# MIMXRT685S_cm33 register map
Vendor: nxp.com; File version: 1.0
CPU: CM33 r2p0, little endian, MPU, FPU, VTOR, 3 interrupt priority bits
Registers are 32-bit, read-write, reset 0x0 unless marked. A register's access mark holds for its fields unless they carry their own. Offsets are from the block's base; [hi:lo] are bit positions; {n}, {i} and the like mark numbered series; 'fields as' and 'values as' point back to an identical list.

## CLKCTL0 — clock ccontroller 0
Base 0x40001000
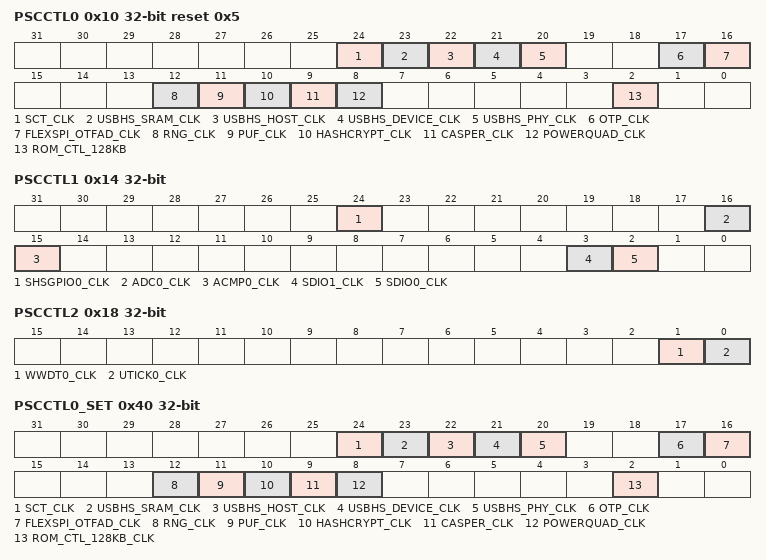
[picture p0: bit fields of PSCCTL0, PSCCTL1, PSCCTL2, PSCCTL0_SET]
0x10 PSCCTL0 reset 0x5 — clock control register 0
  [all] fields
    0=DISABLE_CLOCK; 1=ENABLE_CLOCK
  [24] SCT_CLK — SCT clock control
  [23] USBHS_SRAM_CLK — USBHS RAM clock control
  [22] USBHS_HOST_CLK — USB HOST clock control
  [21] USBHS_DEVICE_CLK — USB DEVICE clock control
  [20] USBHS_PHY_CLK — USB PHY clock control
  [17] OTP_CLK — OTP clock control
  [16] FLEXSPI_OTFAD_CLK — FLEXSPI clock control
  [12] RNG_CLK — RNG clock control
  [11] PUF_CLK — PUF clock control
  [10] HASHCRYPT_CLK — HASHCRYPT clock control
  [9] CASPER_CLK — CAPSER clock control
  [8] POWERQUAD_CLK — powerquad clock control
  [2] ROM_CTL_128KB — 128KB ROM control
0x14 PSCCTL1 — clock control register 1
  [all] fields
    0=DISABLE_CLOCK; 1=ENABLE_CLOCK
  [24] SHSGPIO0_CLK — SHSGPIO0 clock control
  [16] ADC0_CLK — ADC clock control
  [15] ACMP0_CLK — Analog comparator clock control
  [3] SDIO1_CLK — SDIO1 clock control
  [2] SDIO0_CLK — SDIO0 clock control
0x18 PSCCTL2 — clock control register 2
  [1] WWDT0_CLK — wdt clock control
    0=DISABLE_CLOCK; 1=ENABLE_CLOCK
  [0] UTICK0_CLK — utick clock control
    0=DISABLE_CLOCK; 1=ENABLE_CLOCK
0x40 PSCCTL0_SET reset not defined — clock set register 0
  [all] fields
    0=NO_EFFECT; 1=SET_CLOCK (Sets the PSCCTL0 Bit)
  [24] SCT_CLK wo — SCT clock set
  [23] USBHS_SRAM_CLK wo — USBHS RAM clock set
  [22] USBHS_HOST_CLK wo — USB HOST clock set
  [21] USBHS_DEVICE_CLK wo — USB DEVICE clock set
  [20] USBHS_PHY_CLK wo — USB PHY clock set
  [17] OTP_CLK wo — OTP clock set
  [16] FLEXSPI_OTFAD_CLK wo — FLEXSPI clock set
  [12] RNG_CLK wo — RNG clock set
  [11] PUF_CLK wo — PUF clock set
  [10] HASHCRYPT_CLK wo — HASHCRYPT clock set
  [9] CASPER_CLK wo — CAPSER clock set
  [8] POWERQUAD_CLK wo — powerquad clock set
  [2] ROM_CTL_128KB_CLK wo — 128KB ROM controller clock set
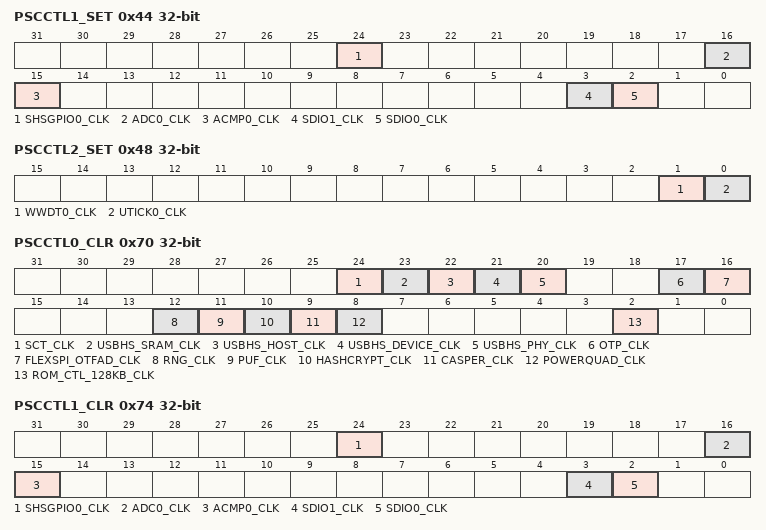
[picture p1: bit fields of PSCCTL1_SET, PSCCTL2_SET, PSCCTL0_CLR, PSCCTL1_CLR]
0x44 PSCCTL1_SET wo reset not defined — clock set register 1
  [all] fields
    0=NO_EFFECT; 1=SET_CLOCK (Sets the PSCCTL1 Bit)
  [24] SHSGPIO0_CLK — SHSGPIO0 clock set
  [16] ADC0_CLK — ADC clock set
  [15] ACMP0_CLK — Analog comparator clock set
  [3] SDIO1_CLK — SDIO1 clock set
  [2] SDIO0_CLK — SDIO0 clock set
0x48 PSCCTL2_SET wo reset not defined — clock set register 2
  [1] WWDT0_CLK — wdt clock set
    0=NO_EFFECT; 1=SET_CLOCK (Sets the PSCCTL2 Bit)
  [0] UTICK0_CLK — utick clock set
    0=NO_EFFECT; 1=SET_CLOCK (Sets the PSCCTL2 Bit)
0x70 PSCCTL0_CLR reset not defined — clock clear register 0
  [all] fields
    0=NO_EFFECT; 1=CLR_CLOCK (Clears the PSCCTL0 Bit)
  [24] SCT_CLK wo — SCT clock clear
  [23] USBHS_SRAM_CLK wo — USBHS RAM clock clear
  [22] USBHS_HOST_CLK wo — USB HOST clock clear
  [21] USBHS_DEVICE_CLK wo — USB DEVICE clock clear
  [20] USBHS_PHY_CLK wo — USB PHY clock clear
  [17] OTP_CLK wo — OTP clock clear
  [16] FLEXSPI_OTFAD_CLK wo — FLEXSPI clock clear
  [12] RNG_CLK wo — RNG clock clear
  [11] PUF_CLK wo — PUF clock clear
  [10] HASHCRYPT_CLK wo — HASHCRYPT clock clear
  [9] CASPER_CLK wo — CAPSER clock clear
  [8] POWERQUAD_CLK wo — powerquad clock clear
  [2] ROM_CTL_128KB_CLK wo — ROM controller clock clear
0x74 PSCCTL1_CLR wo reset not defined — clock clear register 1
  [all] fields
    0=NO_EFFECT; 1=CLR_CLOCK (Clears the PSCCTL1 Bit)
  [24] SHSGPIO0_CLK — SHSGPIO0 clock clear
  [16] ADC0_CLK — ADC clock clear
  [15] ACMP0_CLK — Analog comparator clock clear
  [3] SDIO1_CLK — SDIO1 clock clear
  [2] SDIO0_CLK — SDIO0 clock clear
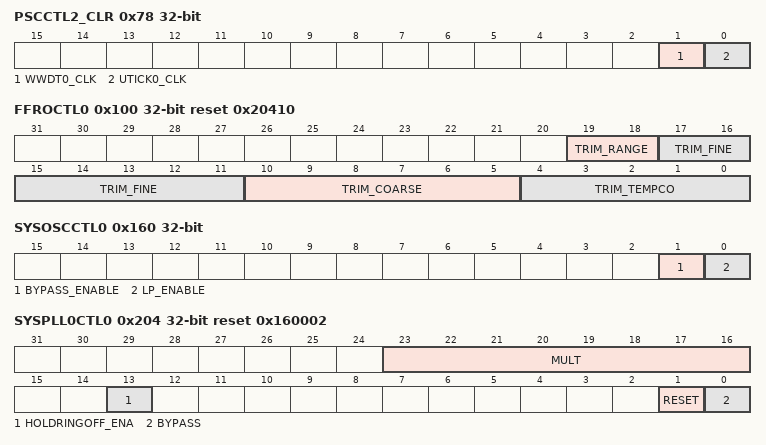
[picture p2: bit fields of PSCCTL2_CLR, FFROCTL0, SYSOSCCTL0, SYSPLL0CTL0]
0x78 PSCCTL2_CLR wo reset not defined — clock clear register 2
  [1] WWDT0_CLK — wdt clock clear
    0=NO_EFFECT; 1=CLR_CLOCK (Clears the PSCCTL2 Bit)
  [0] UTICK0_CLK — utick clock clear
    0=NO_EFFECT; 1=CLR_CLOCK (Clears the PSCCTL2 Bit)
0x100 FFROCTL0 reset 0x20410 — FFRO control 0
  [19:18] TRIM_RANGE — Trims frequency range of FFRO.
    0=FFRO_48MHz (48MHz.); 3=FFRO_60MHz (60MHz.)
  [17:11] TRIM_FINE — Trims fine frequency of FFRO.
  [10:5] TRIM_COARSE — Trims coarse frequency of FFRO.
  [4:0] TRIM_TEMPCO — Trims temperature compensation of FFRO.
0x104 FFROCTL1 — FFRO control 1
  [0] UPDATE — Update Safe Mode Control. In order to change any of the TRIM values, the user first needs to set the update safe mode bit, then proceed to change the respective TRIM values needed, followed by clearing the update safe mode bit.
    0=NORMAL_MODE; 1=UPDATE_SAFE_MODE
0x160 SYSOSCCTL0 — system oscillator control 0
  [1] BYPASS_ENABLE — Enable signal for external bypass clock. . .
    0=NORMAL_MODE; 1=BYPASS_MODE
  [0] LP_ENABLE — Enable signal for low power mode. . .
    0=HP (High Gain Mode(HP).); 1=LP (Low Power mode (LP).)
0x168 SYSOSCBYPASS — system oscillator bypass
  [2:0] SEL — Extenal Clock Source Selection.
    0=EXT_XTAL_CLK (External XTAL Clock.); 1=CLOCK_IN_CLK (Clock IN Clock.); 7=NONE (NONE.this may be selected in order to reduce power when no output is needed.)
0x190 LPOSCCTL0 reset 0x807BC4D4 — low power oscillator control 0
  [31] CLKRDY — Clock ready flag status. LPOSC clock ready takes 64uS.
0x1C0 OSC32KHZCTL0 — 32k oscillator control0
  [0] ENA32KHZ — 32KHz Enable.
    0=DISABLED; 1=ENABLED
0x200 SYSPLL0CLKSEL reset 0x7 — system pll0 clock selection
  [2:0] SEL — System PLL Clock Source Selection. . .
    0=SFRO_CLK (SFRO Clock.); 1=SYSXTAL_CLK (SYSXTALIN Clock.); 2=FFRO_DIV_2 (FFRO Clock Divided by 2.); 7=NONE (None, this may be selected in order to reduce power when no output is needed.)
0x204 SYSPLL0CTL0 reset 0x160002 — system pll0 control0
  [23:16] MULT — Multiplication Factor for FSYSPLL0_OUTPUT:
    16=DIV_16; 17=DIV_17; 20=DIV_20; 22=DIV_22; 27=DIV_27; 33=DIV_33
  [13] HOLDRINGOFF_ENA — Hold Ring Off Control: This bit is used to avoid multi wave within the VCO.
    0=DSIABLE (disbale); 1=ENABLE
  [1] RESET — SYSPLL0 Reset:
    0=NORMAL (SYSPLL0 reset is removed.); 1=FORCED_INTO_RESET (SYSPLL0 is placed into reset.)
  [0] BYPASS — SYSPLL0 BYPASS Mode
    0=PROGRAMMED_CLK (PFD output is PFD programmed clock.); 1=BYPASS (PFD output is PLL Input clock. (Bypass))
0x20C SYSPLL0LOCKTIMEDIV2 reset 0xCAFE — system pll0 lock time
  [15:0] LOCKTIMEDIV2 — SYSPLL0 Lock Time Divide by 2: Programmed lock time is in uS (micro-seconds) and is programmed as half the actual lock time value.
0x210 SYSPLL0NUM reset 0x4DD2F15 — system pll0 number
  [29:0] NUM — This field contains the numerator of the SYSPLL0 fractional loop divider.
0x214 SYSPLL0DENOM reset 0x1FFFFFDB — system pll0 denom
  [29:0] DENOM — This field contains the denominator of the SYSPLL0 fractional loop divider.
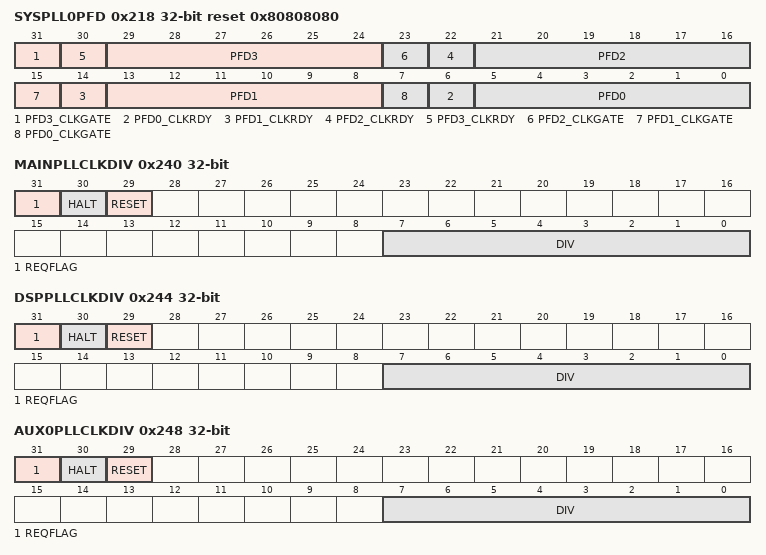
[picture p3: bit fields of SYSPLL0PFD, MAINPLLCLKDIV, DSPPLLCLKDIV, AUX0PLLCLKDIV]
0x218 SYSPLL0PFD reset 0x80808080
  [31] PFD3_CLKGATE — PFD3 Clock Gate: 0: PFD3 clock is not gated. 1: PFD3 clock is gated.
    0=NOT_GATED (PFD3 clock is not gated.); 1=GATED (PFD3 clock is gated.)
  [8n+6] PFD{n}_CLKRDY (n=0..3) — PFD{n} Clock Ready Status Flag: Read as '1' clock ready. Cleared by writing a '1'.
  [8n+5:8n] PFD{n} (n=0..3) — PLL Fractional Divider {n}: Controls the fractional divider value. Valid PFD values are decimal 12-35.
  [23] PFD2_CLKGATE — PFD2 Clock Gate: 0: PFD2 clock is not gated. 1: PFD2 clock is gated.
    0=NOT_GATED (PFD2 clock is not gated.); 1=GATED (PFD2 clock is gated.)
  [15] PFD1_CLKGATE — PFD1 Clock Gate: 0: PFD1 clock is not gated. 1: PFD1 clock is gated.
    0=NOT_GATED (PFD1 clock is not gated.); 1=GATED (PFD1 clock is gated.)
  [7] PFD0_CLKGATE — PFD0 Clock Gate: 0: PFD0 clock is not gated. 1: PFD0 clock is gated
    0=NOT_GATED (PFD0 clock is not gated.); 1=GATED (PFD0 clock is gated.)
0x240 MAINPLLCLKDIV — main pll clk divider
  [31] REQFLAG — Divider status flag. Set when a change is made to the divider value, cleared when the change is complete.
  [30] HALT — Halts the divider counter. The intent is to allow the divider's clock source to be changed without the risk of a glitch at the output.
  [29] RESET — Resets the divider counter. Can be used to make sure a new divider value is used right away rather than completing the previous count.
  [7:0] DIV — Clock Divider Value Selection. . . 0: Divide by 1. ... 255: Divide by 256.
0x244 DSPPLLCLKDIV — dsp pll clk divider
  fields as MAINPLLCLKDIV
0x248 AUX0PLLCLKDIV — aux0 pll clk divider
  fields as MAINPLLCLKDIV
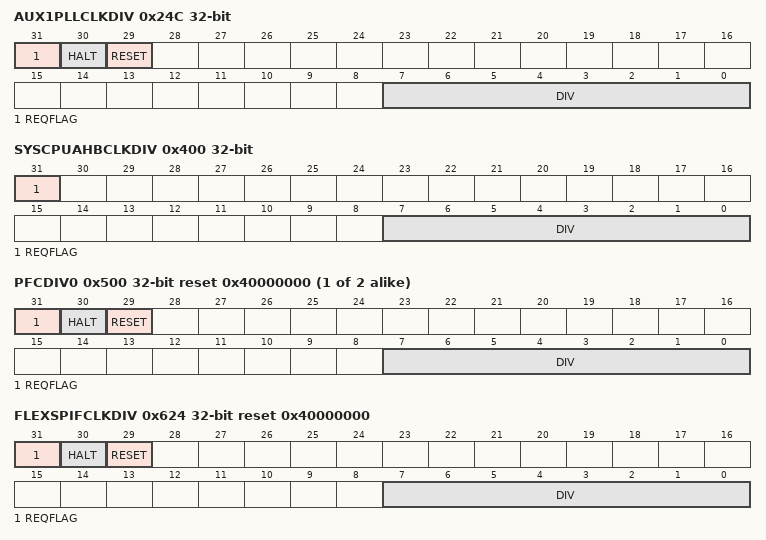
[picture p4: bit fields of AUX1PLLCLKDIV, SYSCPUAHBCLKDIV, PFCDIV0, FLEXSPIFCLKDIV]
0x24C AUX1PLLCLKDIV — aux1 pll clk divider
  fields as MAINPLLCLKDIV
0x400 SYSCPUAHBCLKDIV — system cpu AHB clock divider
  [31] REQFLAG — Divider status flag. Set when a change is made to the divider value, cleared when the change is complete.
  [7:0] DIV — Clock Divider Value Selection. . . 0: Divide by 1. ... 255: Divide by 256.
0x430 MAINCLKSELA — main clock selection A
  [1:0] SEL — Control Main 1st Stage Control Clock Source. . .
    0=FFRO_DIV_4 (FFRO Clock Divided by 4.); 1=SYSXTAL_CLK (SYSXTALIN Clock.); 2=LPOSC (Low Power Oscillator Clock (LPOSC).); 3=FFRO_CLK (FFRO Clock.)
0x434 MAINCLKSELB — main clock selection B
  [1:0] SEL — Main Clock Source Selection. . .
    0=MAIN_1ST_CLK (MAINCLKSELA 1st Stage Clock.); 1=SFRO_CLK (SFRO Clock.); 2=MAIN_PLL_CLK (Main System PLL Clock.); 3=RTC_32K_CLK (RTC 32KHz Clock.)
{0x500+4i} PFCDIV{i} (i=0..1) reset 0x40000000 — PFC divider register N
  [31] REQFLAG — Divider status flag. Set when a change is made to the divider value, cleared when the change is complete.
  [30] HALT — Halts the divider counter. The intent is to allow the divider clock source to be changed without the risk of a glitch at the output.
  [29] RESET — Resets the divider counter. Can be used to make sure a new divider value is used right away rather than completing the previous count.
  [7:0] DIV — Clock Divider Value Selection. . . 0: Divide by 1. ... 255: Divide by 256.
0x620 FLEXSPIFCLKSEL reset 0x7 — FlexSPI FCLK selection
  [2:0] SEL — FlexSPI Functional Clock Source Selection. . .
    0=MAIN_CLK (Main Clock.); 1=MAIN_SYS_PLL_CLK (Main System PLL Clock.); 2=SYSPLL0_AUX0_PLL_Clock; 3=FFRO_CLK (FFRO Clock.); 4=SYSPLL0_AUX1_PLL_Clock; 7=NONE (None, this may be selected in order to reduce power when no output is needed.)
0x624 FLEXSPIFCLKDIV reset 0x40000000 — FlexSPI FCLK divider
  fields as MAINPLLCLKDIV
0x640 SCTFCLKSEL reset 0x7 — SCT FCLK selection
  [2:0] SEL — SCT Functional Clock Source Selection. . .
    0=MAIN_CLK (Main Clock.); 1=MAIN_SYS_PLL_CLK (Main System PLL Clock.); 2=SYSPLL0_AUX0_PLL_Clock; 3=FFRO_CLK (FFRO Clock.); 4=SYSPLL0_AUX1_PLL_Clock; 5=AUDIO_PLL_CLK (AUDIO PLL Clock); 7=NONE (None, this may be selected in order to reduce power when no output is needed.)
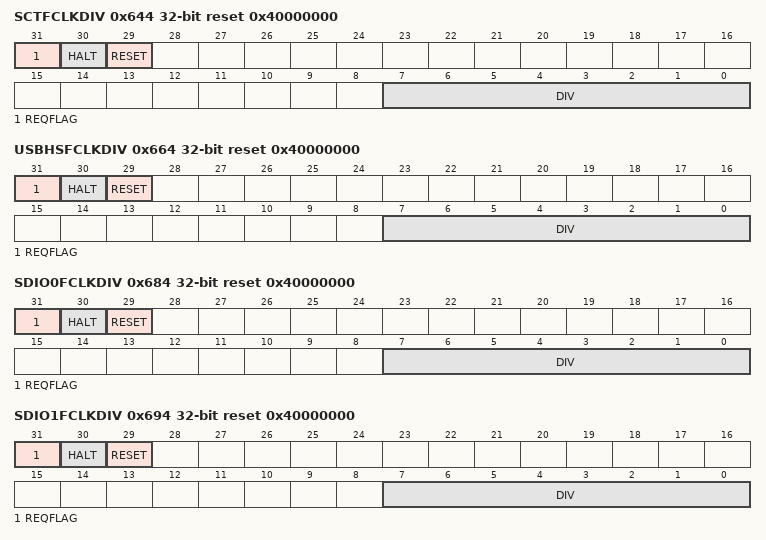
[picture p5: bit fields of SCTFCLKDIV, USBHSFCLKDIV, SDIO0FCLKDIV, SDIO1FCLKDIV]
0x644 SCTFCLKDIV reset 0x40000000 — SCT fclk divider
  fields as PFCDIV0
0x660 USBHSFCLKSEL reset 0x7 — USBHS Fclk selection
  [2:0] SEL — USB HS Functional Clock Source Selection. . .
    0=XTALIN_CLK (XTALIN Clock.); 1=MAIN_CLK (Main Clock.); 7=NONE (None, this may be selected in order to reduce power when no output is needed.)
0x664 USBHSFCLKDIV reset 0x40000000 — USBHS Fclk divider
  fields as PFCDIV0
0x680 SDIO0FCLKSEL reset 0x7 — SDIO0 FCLK selection
  [2:0] SEL — SDIO0 Functional Clock Source Selection. .
    values as FLEXSPIFCLKSEL.SEL
0x684 SDIO0FCLKDIV reset 0x40000000 — SDIO0 FCLK divider
  fields as PFCDIV0
0x690 SDIO1FCLKSEL reset 0x7 — SDIO1 FCLK selection
  [2:0] SEL — SDIO1 Functional Clock Source Selection. .
    values as FLEXSPIFCLKSEL.SEL
0x694 SDIO1FCLKDIV reset 0x40000000 — SDIO1 FCLK divider
  fields as MAINPLLCLKDIV
0x6D0 ADC0FCLKSEL0 reset 0x7 — ADC0 fclk selection 0
  [2:0] SEL — Clock Output Select 1st Stage. . .
    0=SFRO_CLK (SFRO Clock.); 1=XTALIN_CLK (XTALIN Clock.); 2=LPOSC (Low Power Oscillator Clock (LPOSC).); 3=FFRO_CLK (FFRO Clock.); 7=NONE (None, this may be selected in order to reduce power when no output is needed.)
0x6D4 ADC0FCLKSEL1 reset 0x7 — ADC0 fclk selection 1
  [2:0] SEL — ADC Functional Clock Source Selection. . .
    0=ADC0FCLKSEL0_MUX_OUT (ADC0FCLKSEL0 Multiplexed Output.); 1=SYSPLL0_MAIN_CLK (SYSPLL0 MAIN_CLK (PFD0 Output)); 3=SYSPLL0_AUX0_PLL_Clock; 5=SYSPLL0_AUX1_PLL_Clock; 7=NONE (None, this may be selected in order to reduce power when no output is needed.)
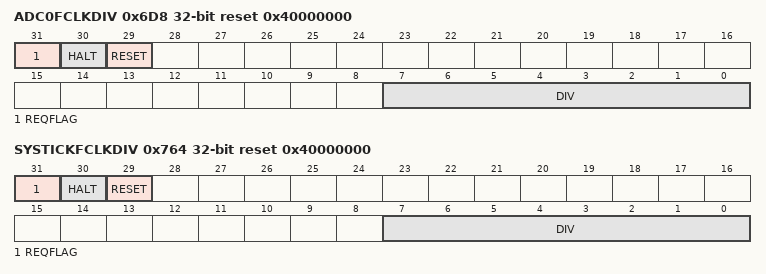
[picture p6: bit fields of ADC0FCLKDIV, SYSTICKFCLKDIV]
0x6D8 ADC0FCLKDIV reset 0x40000000 — ADC0 fclk divider
  fields as MAINPLLCLKDIV
0x700 UTICKFCLKSEL reset 0x7 — UTICK fclk selection
  [2:0] SEL — uTICK Functional Clock Source Selection. .
    0=LPOSC (Low Power Oscillator Clock (LPOSC).); 7=NONE (None, this may be selected in order to reduce power when no output is needed.)
0x720 WDT0FCLKSEL — wdt clock selection
  [2:0] SEL — WDT0 Functional Clock Source Selection. .
    values as UTICKFCLKSEL.SEL
0x730 WAKECLK32KHZSEL reset 0x1 — 32k wake clock selection
  [2:0] SEL — 32KHz Wake Clock Low Power Functional Clock Source Selection. . .
    0=FREQ_32KHZ (32KHz); 1=LPOSC (LPOSC (Divided by 32 by default).); 7=NONE (None, this may be selected in order to reduce power when no output is needed.)
0x734 WAKECLK32KHZDIV reset 0x1F — 32k wake clock divider
  [30] HALT — Halts the divider counter. The intent is to allow the divider's clock source to be changed without the risk of a glitch at the output.
0x760 SYSTICKFCLKSEL reset 0x7 — system tick fclk selection
  [2:0] SEL — SYSTICK Functional Clock Source Selection. . .
    0=SYSTICK_DIV_CLK (Systick Divider Output Clock.); 1=LPOSC (Low Power Oscillator Clock (LPOSC).); 2=RTC_32KHZ (32KHz RTC Clock.); 3=SFRO_CLK (SFRO Clock.); 7=NONE (None, this may be selected in order to reduce power when no output is needed.)
0x764 SYSTICKFCLKDIV reset 0x40000000 — system tick fclk divider
  fields as MAINPLLCLKDIV
